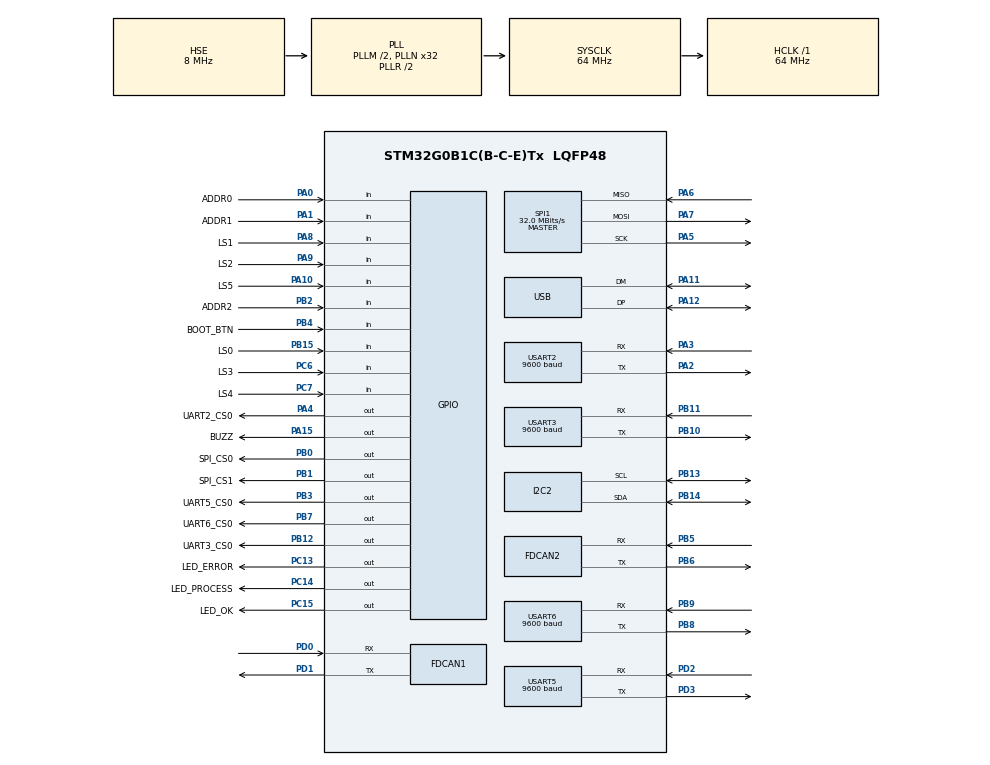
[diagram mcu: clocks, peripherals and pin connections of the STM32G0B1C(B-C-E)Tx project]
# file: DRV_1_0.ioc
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Dma.Request0=USART2_RX
Dma.Request1=USART2_TX
Dma.Request2=USART3_RX
Dma.Request3=USART3_TX
Dma.Request4=USART5_RX
Dma.Request5=USART5_TX
Dma.Request6=USART6_RX
Dma.Request7=USART6_TX
Dma.USART2_RX.0.Direction=DMA_PERIPH_TO_MEMORY
Dma.USART2_RX.0.EventEnable=DISABLE
Dma.USART2_RX.0.Instance=DMA1_Channel1
Dma.USART2_RX.0.MemDataAlignment=DMA_MDATAALIGN_BYTE
Dma.USART2_RX.0.MemInc=DMA_MINC_ENABLE
Dma.USART2_RX.0.Mode=DMA_NORMAL
Dma.USART2_RX.0.PeriphDataAlignment=DMA_PDATAALIGN_BYTE
Dma.USART2_RX.0.PeriphInc=DMA_PINC_DISABLE
Dma.USART2_RX.0.Polarity=HAL_DMAMUX_REQ_GEN_RISING
Dma.USART2_RX.0.Priority=DMA_PRIORITY_LOW
Dma.USART2_RX.0.RequestNumber=1
Dma.USART2_RX.0.SignalID=NONE
Dma.USART2_RX.0.SyncEnable=DISABLE
Dma.USART2_RX.0.SyncPolarity=HAL_DMAMUX_SYNC_NO_EVENT
Dma.USART2_RX.0.SyncRequestNumber=1
Dma.USART2_RX.0.SyncSignalID=NONE
Dma.USART2_TX.1.Direction=DMA_MEMORY_TO_PERIPH
Dma.USART2_TX.1.EventEnable=DISABLE
Dma.USART2_TX.1.Instance=DMA1_Channel2
Dma.USART2_TX.1.MemDataAlignment=DMA_MDATAALIGN_BYTE
Dma.USART2_TX.1.MemInc=DMA_MINC_ENABLE
Dma.USART2_TX.1.Mode=DMA_NORMAL
Dma.USART2_TX.1.PeriphDataAlignment=DMA_PDATAALIGN_BYTE
Dma.USART2_TX.1.PeriphInc=DMA_PINC_DISABLE
Dma.USART2_TX.1.Polarity=HAL_DMAMUX_REQ_GEN_RISING
Dma.USART2_TX.1.Priority=DMA_PRIORITY_LOW
Dma.USART2_TX.1.RequestNumber=1
Dma.USART2_TX.1.SignalID=NONE
Dma.USART2_TX.1.SyncEnable=DISABLE
Dma.USART2_TX.1.SyncPolarity=HAL_DMAMUX_SYNC_NO_EVENT
Dma.USART2_TX.1.SyncRequestNumber=1
Dma.USART2_TX.1.SyncSignalID=NONE
Dma.USART3_RX.2.Direction=DMA_PERIPH_TO_MEMORY
Dma.USART3_RX.2.EventEnable=DISABLE
Dma.USART3_RX.2.Instance=DMA1_Channel3
Dma.USART3_RX.2.MemDataAlignment=DMA_MDATAALIGN_BYTE
Dma.USART3_RX.2.MemInc=DMA_MINC_ENABLE
Dma.USART3_RX.2.Mode=DMA_NORMAL
Dma.USART3_RX.2.PeriphDataAlignment=DMA_PDATAALIGN_BYTE
Dma.USART3_RX.2.PeriphInc=DMA_PINC_DISABLE
Dma.USART3_RX.2.Polarity=HAL_DMAMUX_REQ_GEN_RISING
Dma.USART3_RX.2.Priority=DMA_PRIORITY_LOW
Dma.USART3_RX.2.RequestNumber=1
Dma.USART3_RX.2.SignalID=NONE
Dma.USART3_RX.2.SyncEnable=DISABLE
Dma.USART3_RX.2.SyncPolarity=HAL_DMAMUX_SYNC_NO_EVENT
Dma.USART3_RX.2.SyncRequestNumber=1
Dma.USART3_RX.2.SyncSignalID=NONE
Dma.USART3_TX.3.Direction=DMA_MEMORY_TO_PERIPH
Dma.USART3_TX.3.EventEnable=DISABLE
Dma.USART3_TX.3.Instance=DMA1_Channel4
Dma.USART3_TX.3.MemDataAlignment=DMA_MDATAALIGN_BYTE
Dma.USART3_TX.3.MemInc=DMA_MINC_ENABLE
Dma.USART3_TX.3.Mode=DMA_NORMAL
Dma.USART3_TX.3.PeriphDataAlignment=DMA_PDATAALIGN_BYTE
Dma.USART3_TX.3.PeriphInc=DMA_PINC_DISABLE
Dma.USART3_TX.3.Polarity=HAL_DMAMUX_REQ_GEN_RISING
Dma.USART3_TX.3.Priority=DMA_PRIORITY_LOW
Dma.USART3_TX.3.RequestNumber=1
Dma.USART3_TX.3.SignalID=NONE
Dma.USART3_TX.3.SyncEnable=DISABLE
Dma.USART3_TX.3.SyncPolarity=HAL_DMAMUX_SYNC_NO_EVENT
Dma.USART3_TX.3.SyncRequestNumber=1
Dma.USART3_TX.3.SyncSignalID=NONE
Dma.USART5_RX.4.Direction=DMA_PERIPH_TO_MEMORY
Dma.USART5_RX.4.EventEnable=DISABLE
Dma.USART5_RX.4.Instance=DMA1_Channel5
Dma.USART5_RX.4.MemDataAlignment=DMA_MDATAALIGN_BYTE
Dma.USART5_RX.4.MemInc=DMA_MINC_ENABLE
Dma.USART5_RX.4.Mode=DMA_NORMAL
Dma.USART5_RX.4.PeriphDataAlignment=DMA_PDATAALIGN_BYTE
Dma.USART5_RX.4.PeriphInc=DMA_PINC_DISABLE
Dma.USART5_RX.4.Polarity=HAL_DMAMUX_REQ_GEN_RISING
Dma.USART5_RX.4.Priority=DMA_PRIORITY_LOW
Dma.USART5_RX.4.RequestNumber=1
Dma.USART5_RX.4.SignalID=NONE
Dma.USART5_RX.4.SyncEnable=DISABLE
Dma.USART5_RX.4.SyncPolarity=HAL_DMAMUX_SYNC_NO_EVENT
Dma.USART5_RX.4.SyncRequestNumber=1
Dma.USART5_RX.4.SyncSignalID=NONE
Dma.USART5_TX.5.Direction=DMA_MEMORY_TO_PERIPH
Dma.USART5_TX.5.EventEnable=DISABLE
Dma.USART5_TX.5.Instance=DMA1_Channel6
Dma.USART5_TX.5.MemDataAlignment=DMA_MDATAALIGN_BYTE
Dma.USART5_TX.5.MemInc=DMA_MINC_ENABLE
Dma.USART5_TX.5.Mode=DMA_NORMAL
Dma.USART5_TX.5.PeriphDataAlignment=DMA_PDATAALIGN_BYTE
Dma.USART5_TX.5.PeriphInc=DMA_PINC_DISABLE
Dma.USART5_TX.5.Polarity=HAL_DMAMUX_REQ_GEN_RISING
Dma.USART5_TX.5.Priority=DMA_PRIORITY_LOW
Dma.USART5_TX.5.RequestNumber=1
Dma.USART5_TX.5.SignalID=NONE
Dma.USART5_TX.5.SyncEnable=DISABLE
Dma.USART5_TX.5.SyncPolarity=HAL_DMAMUX_SYNC_NO_EVENT
Dma.USART5_TX.5.SyncRequestNumber=1
Dma.USART5_TX.5.SyncSignalID=NONE
Dma.USART6_RX.6.Direction=DMA_PERIPH_TO_MEMORY
Dma.USART6_RX.6.EventEnable=DISABLE
Dma.USART6_RX.6.Instance=DMA1_Channel7
Dma.USART6_RX.6.MemDataAlignment=DMA_MDATAALIGN_BYTE
Dma.USART6_RX.6.MemInc=DMA_MINC_ENABLE
Dma.USART6_RX.6.Mode=DMA_NORMAL
Dma.USART6_RX.6.PeriphDataAlignment=DMA_PDATAALIGN_BYTE
Dma.USART6_RX.6.PeriphInc=DMA_PINC_DISABLE
Dma.USART6_RX.6.Polarity=HAL_DMAMUX_REQ_GEN_RISING
Dma.USART6_RX.6.Priority=DMA_PRIORITY_LOW
Dma.USART6_RX.6.RequestNumber=1
Dma.USART6_RX.6.SignalID=NONE
Dma.USART6_RX.6.SyncEnable=DISABLE
Dma.USART6_RX.6.SyncPolarity=HAL_DMAMUX_SYNC_NO_EVENT
Dma.USART6_RX.6.SyncRequestNumber=1
Dma.USART6_RX.6.SyncSignalID=NONE
Dma.USART6_TX.7.Direction=DMA_MEMORY_TO_PERIPH
Dma.USART6_TX.7.EventEnable=DISABLE
Dma.USART6_TX.7.Instance=DMA2_Channel1
Dma.USART6_TX.7.MemDataAlignment=DMA_MDATAALIGN_BYTE
Dma.USART6_TX.7.MemInc=DMA_MINC_ENABLE
Dma.USART6_TX.7.Mode=DMA_NORMAL
Dma.USART6_TX.7.PeriphDataAlignment=DMA_PDATAALIGN_BYTE
Dma.USART6_TX.7.PeriphInc=DMA_PINC_DISABLE
Dma.USART6_TX.7.Polarity=HAL_DMAMUX_REQ_GEN_RISING
Dma.USART6_TX.7.Priority=DMA_PRIORITY_LOW
Dma.USART6_TX.7.RequestNumber=1
Dma.USART6_TX.7.SignalID=NONE
Dma.USART6_TX.7.SyncEnable=DISABLE
Dma.USART6_TX.7.SyncPolarity=HAL_DMAMUX_SYNC_NO_EVENT
Dma.USART6_TX.7.SyncRequestNumber=1
Dma.USART6_TX.7.SyncSignalID=NONE
FDCAN1.CalculateBaudRateNominal=800000
FDCAN1.CalculateTimeBitNominal=1250
FDCAN1.CalculateTimeQuantumNominal=250.0
FDCAN2.CalculateBaudRateNominal=800000
FDCAN2.CalculateTimeBitNominal=1250
FDCAN2.CalculateTimeQuantumNominal=250.0
I2C2.Timing=0x10707DBC
Mcu.Family=STM32G0
Mcu.Name=STM32G0B1C(B-C-E)Tx
Mcu.Package=LQFP48
NVIC.DMA1_Ch4_7_DMA2_Ch1_5_DMAMUX1_OVR_IRQn=true\:0\:0\:false\:false\:true\:false\:true\:true
NVIC.DMA1_Channel1_IRQn=true\:0\:0\:false\:false\:true\:false\:true\:true
NVIC.DMA1_Channel2_3_IRQn=true\:0\:0\:false\:false\:true\:false\:true\:true
NVIC.I2C2_3_IRQn=true\:3\:0\:true\:false\:true\:true\:true\:true
NVIC.SPI1_IRQn=true\:3\:0\:true\:false\:true\:true\:true\:true
NVIC.TIM14_IRQn=true\:3\:0\:true\:false\:true\:true\:true\:true
NVIC.TIM15_IRQn=true\:3\:0\:true\:false\:true\:true\:true\:true
NVIC.TIM16_FDCAN_IT0_IRQn=true\:1\:0\:true\:false\:true\:true\:true\:true
NVIC.TIM17_FDCAN_IT1_IRQn=true\:1\:0\:true\:false\:true\:true\:true\:true
NVIC.USART2_LPUART2_IRQn=true\:1\:0\:true\:false\:true\:true\:true\:true
NVIC.USART3_4_5_6_LPUART1_IRQn=true\:1\:0\:true\:false\:true\:true\:true\:true
PA0.GPIO_Label=ADDR0
PA0.Signal=GPIO_Input
PA1.GPIO_Label=ADDR1
PA1.Signal=GPIO_Input
PA10.GPIO_Label=LS5
PA10.Signal=GPIO_Input
PA11\ [PA9].Mode=Device
PA11\ [PA9].Signal=USB_DM
PA12\ [PA10].Mode=Device
PA12\ [PA10].Signal=USB_DP
PA13.Mode=Serial_Wire
PA13.Signal=SYS_SWDIO
PA14-BOOT0.Mode=Serial_Wire
PA14-BOOT0.Signal=SYS_SWCLK
PA15.GPIO_Label=BUZZ
PA15.Signal=GPIO_Output
PA2.Mode=Asynchronous
PA2.Signal=USART2_TX
PA3.Mode=Asynchronous
PA3.Signal=USART2_RX
PA4.GPIO_Label=UART2_CS0
PA4.Signal=GPIO_Output
PA5.Mode=Full_Duplex_Master
PA5.Signal=SPI1_SCK
PA6.Mode=Full_Duplex_Master
PA6.Signal=SPI1_MISO
PA7.Mode=Full_Duplex_Master
PA7.Signal=SPI1_MOSI
PA8.GPIO_Label=LS1
PA8.Signal=GPIO_Input
PA9.GPIO_Label=LS2
PA9.Signal=GPIO_Input
PB0.GPIO_Label=SPI_CS0
PB0.Signal=GPIO_Output
PB1.GPIO_Label=SPI_CS1
PB1.Signal=GPIO_Output
PB10.Mode=Asynchronous
PB10.Signal=USART3_TX
PB11.Mode=Asynchronous
PB11.Signal=USART3_RX
PB12.GPIO_Label=UART3_CS0
PB12.Signal=GPIO_Output
PB13.Mode=I2C
PB13.Signal=I2C2_SCL
PB14.Mode=I2C
PB14.Signal=I2C2_SDA
PB15.GPIO_Label=LS0
PB15.Signal=GPIO_Input
PB2.GPIO_Label=ADDR2
PB2.Signal=GPIO_Input
PB3.GPIO_Label=UART5_CS0
PB3.Signal=GPIO_Output
PB4.GPIO_Label=BOOT_BTN
PB4.Signal=GPIO_Input
PB5.Mode=FDCAN_Activate
PB5.Signal=FDCAN2_RX
PB6.Mode=FDCAN_Activate
PB6.Signal=FDCAN2_TX
PB7.GPIO_Label=UART6_CS0
PB7.Signal=GPIO_Output
PB8.Mode=Asynchronous
PB8.Signal=USART6_TX
PB9.Mode=Asynchronous
PB9.Signal=USART6_RX
PC13.GPIO_Label=LED_ERROR
PC13.Signal=GPIO_Output
PC14-OSC32_IN\ (PC14).GPIO_Label=LED_PROCESS
PC14-OSC32_IN\ (PC14).Signal=GPIO_Output
PC15-OSC32_OUT\ (PC15).GPIO_Label=LED_OK
PC15-OSC32_OUT\ (PC15).Signal=GPIO_Output
PC6.GPIO_Label=LS3
PC6.Signal=GPIO_Input
PC7.GPIO_Label=LS4
PC7.Signal=GPIO_Input
PD0.Mode=FDCAN_Activate
PD0.Signal=FDCAN1_RX
PD1.Mode=FDCAN_Activate
PD1.Signal=FDCAN1_TX
PD2.Mode=Asynchronous
PD2.Signal=USART5_RX
PD3.Mode=Asynchronous
PD3.Signal=USART5_TX
PF0-OSC_IN\ (PF0).Mode=HSE-External-Oscillator
PF0-OSC_IN\ (PF0).Signal=RCC_OSC_IN
PF1-OSC_OUT\ (PF1).Mode=HSE-External-Oscillator
PF1-OSC_OUT\ (PF1).Signal=RCC_OSC_OUT
ProjectManager.HeapSize=0x2000
ProjectManager.StackSize=0x4000
ProjectManager.TargetToolchain=STM32CubeIDE
RCC.ADCFreq_Value=64000000
RCC.AHBFreq_Value=64000000
RCC.CortexFreq_Value=64000000
RCC.EXTERNAL_CLOCK_VALUE=48000
RCC.HCLKFreq_Value=64000000
RCC.HSE_VALUE=8000000
RCC.HSI48_VALUE=48000000
RCC.HSI_VALUE=16000000
RCC.LSE_VALUE=32768
RCC.PLLM=RCC_PLLM_DIV2
RCC.PLLN=32
RCC.PLLSourceVirtual=RCC_PLLSOURCE_HSE
RCC.SYSCLKFreq_VALUE=64000000
RCC.SYSCLKSource=RCC_SYSCLKSOURCE_PLLCLK
RCC.USBFreq_Value=48000000
RCC.VCOOutputFreq_Value=128000000
SPI1.BaudRatePrescaler=SPI_BAUDRATEPRESCALER_2
SPI1.CalculateBaudRate=32.0 MBits/s
SPI1.Direction=SPI_DIRECTION_2LINES
SPI1.Mode=SPI_MODE_MASTER
SPI1.VirtualType=VM_MASTER
TIM14.Period=100
TIM14.Prescaler=6399
TIM15.Period=200
TIM15.Prescaler=6399
TIM16.Period=500
TIM16.Prescaler=6399
TIM17.Period=1000
TIM17.Prescaler=6399
USART2.BaudRate=9600
USART2.VirtualMode-Asynchronous=VM_ASYNC
USART3.BaudRate=9600
USART3.VirtualMode-Asynchronous=VM_ASYNC
USART5.BaudRate=9600
USART5.VirtualMode-Asynchronous=VM_ASYNC
USART6.BaudRate=9600
USART6.VirtualMode-Asynchronous=VM_ASYNC
USB_DEVICE.CLASS_NAME_FS=DFU
USB_DEVICE.VirtualMode=Dfu
USB_DEVICE.VirtualModeFS=Dfu_FS
VP_SYS_VS_DBSignals.Mode=DisableDeadBatterySignals
VP_TIM14_VS_ClockSourceINT.Mode=Enable_Timer
VP_TIM15_VS_ClockSourceINT.Mode=Internal
VP_TIM16_VS_ClockSourceINT.Mode=Enable_Timer
VP_TIM17_VS_ClockSourceINT.Mode=Enable_Timer
VP_USB_DEVICE_VS_USB_DEVICE_DFU_FS.Mode=DFU_FS
board=custom

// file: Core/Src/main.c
/* USER CODE BEGIN Header */
/**
  ******************************************************************************
  * @file           : main.c
  * @brief          : Main program body
  ******************************************************************************
  * @attention
  *
  * Copyright (c) 2023 STMicroelectronics.
  * All rights reserved.
  *
  * This software is licensed under terms that can be found in the LICENSE file
  * in the root directory of this software component.
  * If no LICENSE file comes with this software, it is provided AS-IS.
  *
  ******************************************************************************
  */
/* USER CODE END Header */
#include "main.h"
#include "dma.h"
#include "fdcan.h"
#include "i2c.h"
#include "spi.h"
#include "tim.h"
#include "usart.h"
#include "usb_device.h"
#include "gpio.h"

/* USER CODE BEGIN Includes */
#include "process.h"
/* USER CODE END Includes */

void SystemClock_Config(void);

int main(void)
{

  /* MCU Configuration--------------------------------------------------------*/

  /* Reset of all peripherals, Initializes the Flash interface and the Systick. */
  HAL_Init();

  /* Configure the system clock */
  SystemClock_Config();

  /* Initialize all configured peripherals */
  MX_GPIO_Init();
  MX_DMA_Init();
  MX_FDCAN1_Init();
  MX_FDCAN2_Init();
  MX_I2C2_Init();
  MX_SPI1_Init();
  MX_USART2_UART_Init();
  MX_USART3_UART_Init();
  MX_USART5_UART_Init();
  MX_USART6_UART_Init();
  MX_USB_Device_Init();
  MX_TIM14_Init();
  MX_TIM15_Init();
  MX_TIM16_Init();
  MX_TIM17_Init();
  /* USER CODE BEGIN 2 */
  PROCESS_Init();
  /* USER CODE END 2 */

  /* Infinite loop */
  /* USER CODE BEGIN WHILE */
  while (1)
  {
	  PROCESS_Main();
    /* USER CODE END WHILE */

  }
}

void SystemClock_Config(void)
{
  RCC_OscInitTypeDef RCC_OscInitStruct = {0};
  RCC_ClkInitTypeDef RCC_ClkInitStruct = {0};

  /** Configure the main internal regulator output voltage
  */
  HAL_PWREx_ControlVoltageScaling(PWR_REGULATOR_VOLTAGE_SCALE1);

  /** Initializes the RCC Oscillators according to the specified parameters
  * in the RCC_OscInitTypeDef structure.
  */
  RCC_OscInitStruct.OscillatorType = RCC_OSCILLATORTYPE_HSE|RCC_OSCILLATORTYPE_HSI48;
  RCC_OscInitStruct.HSEState = RCC_HSE_ON;
  RCC_OscInitStruct.HSI48State = RCC_HSI48_ON;
  RCC_OscInitStruct.PLL.PLLState = RCC_PLL_ON;
  RCC_OscInitStruct.PLL.PLLSource = RCC_PLLSOURCE_HSE;
  RCC_OscInitStruct.PLL.PLLM = RCC_PLLM_DIV2;
  RCC_OscInitStruct.PLL.PLLN = 32;
  RCC_OscInitStruct.PLL.PLLP = RCC_PLLP_DIV2;
  RCC_OscInitStruct.PLL.PLLQ = RCC_PLLQ_DIV2;
  RCC_OscInitStruct.PLL.PLLR = RCC_PLLR_DIV2;
  if (HAL_RCC_OscConfig(&RCC_OscInitStruct) != HAL_OK)
  {
    Error_Handler();
  }

  /** Initializes the CPU, AHB and APB buses clocks
  */
  RCC_ClkInitStruct.ClockType = RCC_CLOCKTYPE_HCLK|RCC_CLOCKTYPE_SYSCLK
                              |RCC_CLOCKTYPE_PCLK1;
  RCC_ClkInitStruct.SYSCLKSource = RCC_SYSCLKSOURCE_PLLCLK;
  RCC_ClkInitStruct.AHBCLKDivider = RCC_SYSCLK_DIV1;
  RCC_ClkInitStruct.APB1CLKDivider = RCC_HCLK_DIV1;

  if (HAL_RCC_ClockConfig(&RCC_ClkInitStruct, FLASH_LATENCY_2) != HAL_OK)
  {
    Error_Handler();
  }
}

void Error_Handler(void)
{
  __disable_irq();
  while (1)
  {
  }
}
